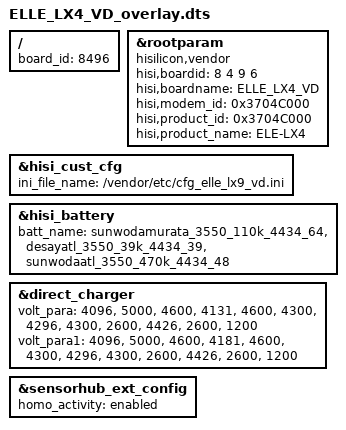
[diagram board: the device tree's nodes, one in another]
/**
 * Copyright (C) 2014 Hisilicon Ltd.
 *
 *  This program is free software; you can redistribute it and/or modify
 *  it under the terms of the GNU General Public License version 2 as
 *  publishhed by the Free Software Foundation.
 */

/dts-v1/;
/plugin/;
/include/ "sunwodamurata_3550_110k_4434_64.dtsi"
/include/ "desayatl_3550_39k_4434_39.dtsi"
/include/ "sunwodaatl_3550_470k_4434_48.dtsi"
/include/ "ELLE_LX4_VC2_overlay.dtsi"
/include/ "ELLE_LX4_VD_pin.dtsi"
/include/ "ELLE_LX4_VD_modem_pin.dtsi"

/ {
    board_id = <8496>;
};
    &rootparam{
		compatible = "hisilicon,vendor";
		hisi,boardid = <8 4 9 6>;
		hisi,boardname = "ELLE_LX4_VD";
		hisi,modem_id = <0x3704C000>;
		hisi,product_id = <0x3704C000>;
		hisi,product_name = "ELE-LX4";
	};

    /*hisi customize*/
    &hisi_cust_cfg {
        ini_file_name = "/vendor/etc/cfg_elle_lx9_vd.ini";
    };

	&hisi_battery {
		batt_name = <&sunwodamurata_3550_110k_4434_64 &desayatl_3550_39k_4434_39 &sunwodaatl_3550_470k_4434_48>;
	};

	&direct_charger {
		volt_para =
			"4096", "5000", "4600",
			"4131", "4600", "4300",
			"4296", "4300", "2600",
			"4426", "2600", "1200";
		volt_para1 =
			"4096", "5000", "4600",
			"4181", "4600", "4300",
			"4296", "4300", "2600",
			"4426", "2600", "1200";
	};

	&sensorhub_ext_config {
        homo_activity = "enabled";
    }; 
